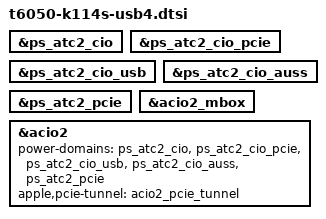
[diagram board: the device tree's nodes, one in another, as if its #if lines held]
// SPDX-License-Identifier: GPL-2.0+ OR MIT
/*
 * K114s (MacBook Pro 14-inch PROLED XDR, M5 Pro): the USB4/Thunderbolt routers of both USB-C
 * ports, for candidate r3-usb4 (issue #61). Include after t6050-k114s-common.dtsi and
 * t6050-k114s-usb.dtsi, built with K114S_R1_USB.
 *
 * Nothing here is board-specific text. The K114s (27.2, 26B8125) ADT's /arm-io/acio1 and acio2
 * (and their acio-cpu, interrupts, port numbers, lstx pins) sit at the same addresses as the
 * J714s's, which aurora-silicon/linux already describes:
 *   ATC1 left-front: t6050-j714s-left-usb4.dtsi          (pull request 1791, J714s, booted with a USB4 NVMe enclosure)
 *   ATC2 right:      t6050-max-atc2-router.dtsi          (pull request 1841, K114c)
 * so this file includes those and adds only what the K114s side must say. tests/k114s-adt-usb4-facts.py
 * checks that equality against this Mac's own ADT.
 *
 * Needs a kernel tree that has both files (aurora-silicon/linux at or after 1841 and 1791) and
 * patches/linux/usb4/0001, whose guards in t6050-max.dtsi and t6050-peripherals.dtsi key on
 * T6050_K114S_USB4. The top-level dts (t6050-k114s-r3-usb4.dts) defines it before its includes.
 *
 * Everything the kernel gets comes from this compiled tree: the router, NHI, DART, tunnel and PHY
 * tunables, and the host DROM of the left router. tests/k114s-adt-usb4-facts.py checks each against
 * this Mac's ADT. The tree has no usb4_N_rc, usb4-N-acio or usb4_N_nhi aliases, which is how
 * Aura's dt_set_acio_tunables() finds the nodes, so the boot loader replaces none of it. The right
 * router has no host DROM here (the DROM is not in the repository): K114S_USB4_DROM below can name
 * a generated file that sets it from the ADT, as the PMP tunables file is.
 *
 * Copyright The Asahi Linux Contributors
 */

#ifndef K114S_R1_USB
#error "t6050-k114s-usb4.dtsi extends the K114S_R1_USB section of t6050-k114s-common.dtsi"
#endif

/* ATC2 (right): router, as the K114c has it. First: it sets the AOP pin reservation to expose only pin 81. */
#include "t6050-max-atc2-router.dtsi"

/* ATC1 (left-front): router, mailbox, DART, NHI, PCIe tunnel, supplier domains; hpm1 port@3.
 * Last of the two: its gpio-reserved-ranges exposes both LSTX pins (79 and 81), as on the J714s. */
#include "t6050-j714s-left-usb4.dtsi"

/* The right router's suppliers, disabled in the inventory (as in the K114c's tree) */
&ps_atc2_cio {
	status = "okay";
};

&ps_atc2_cio_pcie {
	status = "okay";
};

&ps_atc2_cio_usb {
	status = "okay";
};

&ps_atc2_cio_auss {
	status = "okay";
};

&ps_atc2_pcie {
	status = "okay";
};

&acio2_mbox {
	status = "okay";
};

&acio2 {
	status = "okay";
	power-domains = <&ps_atc2_cio>, <&ps_atc2_cio_pcie>,
			<&ps_atc2_cio_usb>, <&ps_atc2_cio_auss>, <&ps_atc2_pcie>;
	apple,pcie-tunnel = <&acio2_pcie_tunnel>;
};

#ifdef K114S_USB4_DROM
#include K114S_USB4_DROM
#endif
